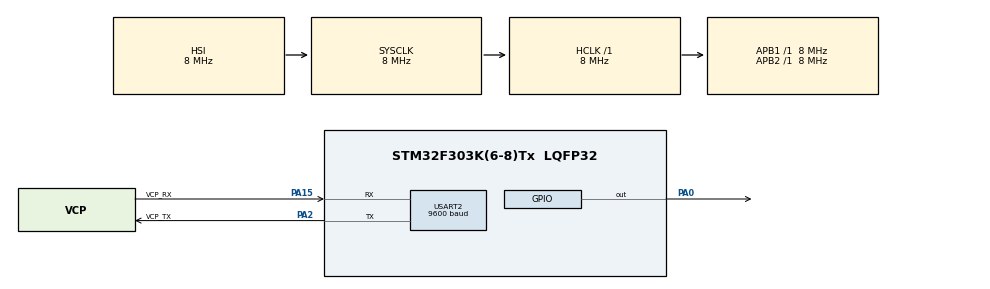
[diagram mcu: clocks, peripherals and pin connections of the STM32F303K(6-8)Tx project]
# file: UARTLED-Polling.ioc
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Mcu.Family=STM32F3
Mcu.Name=STM32F303K(6-8)Tx
Mcu.Package=LQFP32
NVIC.PriorityGroup=NVIC_PRIORITYGROUP_4
PA0.Signal=GPIO_Output
PA13.GPIO_Label=SWDIO
PA13.Signal=SYS_JTMS-SWDIO
PA14.GPIO_Label=SWCLK
PA14.Signal=SYS_JTCK-SWCLK
PA15.GPIO_Label=VCP_RX
PA15.Mode=Asynchronous
PA15.Signal=USART2_RX
PA2.GPIO_Label=VCP_TX
PA2.Mode=Asynchronous
PA2.Signal=USART2_TX
PF0\ /\ OSC_IN.GPIO_Label=MCO
PF0\ /\ OSC_IN.Signal=RCC_OSC_IN
ProjectManager.HeapSize=0x200
ProjectManager.StackSize=0x400
ProjectManager.TargetToolchain=TrueSTUDIO
RCC.AHBFreq_Value=8000000
RCC.APB1Freq_Value=8000000
RCC.APB2Freq_Value=8000000
RCC.CortexFreq_Value=8000000
RCC.HSE_VALUE=8000000
RCC.HSI_VALUE=8000000
RCC.SYSCLKFreq_VALUE=8000000
USART2.BaudRate=9600
USART2.Parity=PARITY_EVEN
USART2.VirtualMode-Asynchronous=VM_ASYNC
USART2.WordLength=WORDLENGTH_9B
board=NUCLEO-F303K8

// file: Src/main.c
/**
  ******************************************************************************
  * @file           : main.c
  * @brief          : Main program body
  ******************************************************************************
  ** This notice applies to any and all portions of this file
  * that are not between comment pairs USER CODE BEGIN and
  * USER CODE END. Other portions of this file, whether
  * inserted by the user or by software development tools
  * are owned by their respective copyright owners.
  *
  * COPYRIGHT(c) 2018 STMicroelectronics
  *
  * Redistribution and use in source and binary forms, with or without modification,
  * are permitted provided that the following conditions are met:
  *   1. Redistributions of source code must retain the above copyright notice,
  *      this list of conditions and the following disclaimer.
  *   2. Redistributions in binary form must reproduce the above copyright notice,
  *      this list of conditions and the following disclaimer in the documentation
  *      and/or other materials provided with the distribution.
  *   3. Neither the name of STMicroelectronics nor the names of its contributors
  *      may be used to endorse or promote products derived from this software
  *      without specific prior written permission.
  *
  * THIS SOFTWARE IS PROVIDED BY THE COPYRIGHT HOLDERS AND CONTRIBUTORS "AS IS"
  * AND ANY EXPRESS OR IMPLIED WARRANTIES, INCLUDING, BUT NOT LIMITED TO, THE
  * IMPLIED WARRANTIES OF MERCHANTABILITY AND FITNESS FOR A PARTICULAR PURPOSE ARE
  * DISCLAIMED. IN NO EVENT SHALL THE COPYRIGHT HOLDER OR CONTRIBUTORS BE LIABLE
  * FOR ANY DIRECT, INDIRECT, INCIDENTAL, SPECIAL, EXEMPLARY, OR CONSEQUENTIAL
  * DAMAGES (INCLUDING, BUT NOT LIMITED TO, PROCUREMENT OF SUBSTITUTE GOODS OR
  * SERVICES; LOSS OF USE, DATA, OR PROFITS; OR BUSINESS INTERRUPTION) HOWEVER
  * CAUSED AND ON ANY THEORY OF LIABILITY, WHETHER IN CONTRACT, STRICT LIABILITY,
  * OR TORT (INCLUDING NEGLIGENCE OR OTHERWISE) ARISING IN ANY WAY OUT OF THE USE
  * OF THIS SOFTWARE, EVEN IF ADVISED OF THE POSSIBILITY OF SUCH DAMAGE.
  *
  ******************************************************************************
  */
#include "main.h"
#include "stm32f3xx_hal.h"
#include "string.h"
#include "stdlib.h"
/* USER CODE BEGIN Includes */

#define LINE1 "\r\nIntroduce un numero"
#define LINE2 "\r\n		1) Enciende LED"
#define LINE3 "\r\n		2) Apaga LED"
#define LED_ON "\r\nLed Encendido"
#define LED_OFF "\r\nLed Apagado"
#define ERROR_INPUT "\r\nValor Invalido"
#define PROMT "\r\n>>"
#define RX_BUFF_SIZE 3

/* USER CODE END Includes */

UART_HandleTypeDef huart2;

/* USER CODE BEGIN PV */
/* Private variables ---------------------------------------------------------*/

/* USER CODE END PV */

void SystemClock_Config(void);
static void MX_GPIO_Init(void);
static void MX_USART2_UART_Init(void);

/* USER CODE BEGIN PFP */
/* Private function prototypes -----------------------------------------------*/
//Lee opcion UART
uint8_t get_option(UART_HandleTypeDef* huart);
//imprime menu por UART (COM3)
void print_menu(UART_HandleTypeDef* huart);
//Enciende LED EN PA0
void operaLed(uint8_t estado,UART_HandleTypeDef* huart);
/* USER CODE END PFP */

int main(void)
{
  /* USER CODE BEGIN 1 */
	uint8_t op = 2;
  /* USER CODE END 1 */

  /* MCU Configuration----------------------------------------------------------*/

  /* Reset of all peripherals, Initializes the Flash interface and the Systick. */
  HAL_Init();

  /* Configure the system clock */
  SystemClock_Config();

  /* Initialize all configured peripherals */
  MX_GPIO_Init();
  MX_USART2_UART_Init();

  /* Infinite loop */
  while (1)
  {
	 print_menu(&huart2);
	 op = get_option(&huart2);
	 operaLed(op,&huart2);
  }

}
//Lee opcion UART
uint8_t get_option(UART_HandleTypeDef* huart){
	uint8_t rx_buff[RX_BUFF_SIZE];
	if(HAL_UART_Receive(huart,rx_buff,RX_BUFF_SIZE,HAL_MAX_DELAY) != HAL_OK)
		Error_Handler();
	return atoi(rx_buff);
}
//imprime menu por UART (COM3)
void print_menu(UART_HandleTypeDef* huart){
	  if(HAL_UART_Transmit(huart,(uint8_t*)LINE1,strlen(LINE1),HAL_MAX_DELAY) != HAL_OK)
		  Error_Handler();
	  if(HAL_UART_Transmit(huart,(uint8_t*)LINE2,strlen(LINE2),HAL_MAX_DELAY) != HAL_OK)
		  Error_Handler();
	  if(HAL_UART_Transmit(huart,(uint8_t*)LINE3,strlen(LINE3),HAL_MAX_DELAY) != HAL_OK)
		  Error_Handler();
	  if(HAL_UART_Transmit(huart,(uint8_t*)PROMT,strlen(PROMT),HAL_MAX_DELAY) != HAL_OK)
		  Error_Handler();
}
//Enciende LED EN PA0
void operaLed(uint8_t estado,UART_HandleTypeDef* huart){
	switch(estado){
	case 0:
			HAL_GPIO_WritePin(GPIOA,GPIO_PIN_0,GPIO_PIN_RESET);
			if(HAL_UART_Transmit(huart,(uint8_t*)LED_OFF,strlen(LED_OFF),HAL_MAX_DELAY) != HAL_OK)
				  Error_Handler();
			break;
	case 1:
			HAL_GPIO_WritePin(GPIOA,GPIO_PIN_0,GPIO_PIN_SET);
			if(HAL_UART_Transmit(huart,(uint8_t*)LED_ON,strlen(LED_ON),HAL_MAX_DELAY) != HAL_OK)
				  Error_Handler();
			break;
	default:
			if(HAL_UART_Transmit(huart,(uint8_t*)ERROR_INPUT,strlen(ERROR_INPUT),HAL_MAX_DELAY) != HAL_OK)
				Error_Handler();
			break;
	}
}

void SystemClock_Config(void)
{

  RCC_OscInitTypeDef RCC_OscInitStruct;
  RCC_ClkInitTypeDef RCC_ClkInitStruct;

    /**Initializes the CPU, AHB and APB busses clocks
    */
  RCC_OscInitStruct.OscillatorType = RCC_OSCILLATORTYPE_HSI;
  RCC_OscInitStruct.HSIState = RCC_HSI_ON;
  RCC_OscInitStruct.HSICalibrationValue = 16;
  RCC_OscInitStruct.PLL.PLLState = RCC_PLL_NONE;
  if (HAL_RCC_OscConfig(&RCC_OscInitStruct) != HAL_OK)
  {
    _Error_Handler(__FILE__, __LINE__);
  }

    /**Initializes the CPU, AHB and APB busses clocks
    */
  RCC_ClkInitStruct.ClockType = RCC_CLOCKTYPE_HCLK|RCC_CLOCKTYPE_SYSCLK
                              |RCC_CLOCKTYPE_PCLK1|RCC_CLOCKTYPE_PCLK2;
  RCC_ClkInitStruct.SYSCLKSource = RCC_SYSCLKSOURCE_HSI;
  RCC_ClkInitStruct.AHBCLKDivider = RCC_SYSCLK_DIV1;
  RCC_ClkInitStruct.APB1CLKDivider = RCC_HCLK_DIV1;
  RCC_ClkInitStruct.APB2CLKDivider = RCC_HCLK_DIV1;

  if (HAL_RCC_ClockConfig(&RCC_ClkInitStruct, FLASH_LATENCY_0) != HAL_OK)
  {
    _Error_Handler(__FILE__, __LINE__);
  }

    /**Configure the Systick interrupt time
    */
  HAL_SYSTICK_Config(HAL_RCC_GetHCLKFreq()/1000);

    /**Configure the Systick
    */
  HAL_SYSTICK_CLKSourceConfig(SYSTICK_CLKSOURCE_HCLK);

  /* SysTick_IRQn interrupt configuration */
  HAL_NVIC_SetPriority(SysTick_IRQn, 0, 0);
}

/* USART2 init function */
static void MX_USART2_UART_Init(void)
{

  huart2.Instance = USART2;
  huart2.Init.BaudRate = 9600;
  huart2.Init.WordLength = UART_WORDLENGTH_9B;
  huart2.Init.StopBits = UART_STOPBITS_1;
  huart2.Init.Parity = UART_PARITY_EVEN;
  huart2.Init.Mode = UART_MODE_TX_RX;
  huart2.Init.HwFlowCtl = UART_HWCONTROL_NONE;
  huart2.Init.OverSampling = UART_OVERSAMPLING_16;
  huart2.Init.OneBitSampling = UART_ONE_BIT_SAMPLE_DISABLE;
  huart2.AdvancedInit.AdvFeatureInit = UART_ADVFEATURE_NO_INIT;
  if (HAL_UART_Init(&huart2) != HAL_OK)
  {
    _Error_Handler(__FILE__, __LINE__);
  }

}

/** Configure pins as
        * Analog
        * Input
        * Output
        * EVENT_OUT
        * EXTI
*/
static void MX_GPIO_Init(void)
{

  GPIO_InitTypeDef GPIO_InitStruct;

  /* GPIO Ports Clock Enable */
  __HAL_RCC_GPIOF_CLK_ENABLE();
  __HAL_RCC_GPIOA_CLK_ENABLE();

  /*Configure GPIO pin Output Level */
  HAL_GPIO_WritePin(GPIOA, GPIO_PIN_0, GPIO_PIN_RESET);

  /*Configure GPIO pin : PA0 */
  GPIO_InitStruct.Pin = GPIO_PIN_0;
  GPIO_InitStruct.Mode = GPIO_MODE_OUTPUT_PP;
  GPIO_InitStruct.Pull = GPIO_NOPULL;
  GPIO_InitStruct.Speed = GPIO_SPEED_FREQ_LOW;
  HAL_GPIO_Init(GPIOA, &GPIO_InitStruct);

}

void _Error_Handler(char *file, int line)
{
}

/************************ (C) COPYRIGHT STMicroelectronics *****END OF FILE****/
